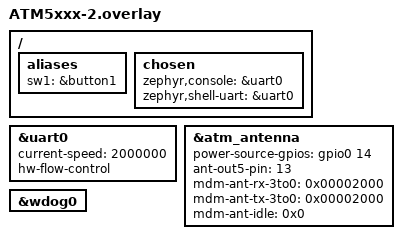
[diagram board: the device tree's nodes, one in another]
/*
 * Copyright (c) 2026 Atmosic
 *
 * SPDX-License-Identifier: LicenseRef-Atmosic
 */

/ {
	aliases {
		sw1 = &button1;
	};

	chosen {
		zephyr,console = &uart0;
		zephyr,shell-uart = &uart0;
	};
};

&uart0 {
	status = "okay";
	current-speed = <2000000>;
	hw-flow-control;
};

&atm_antenna {
	status = "okay";
	power-source-gpios = <&gpio0 14 GPIO_ACTIVE_HIGH>;
	ant-out5-pin = <13>;
	mdm-ant-rx-3to0 = <0x00002000>;
	mdm-ant-tx-3to0 = <0x00002000>;
	mdm-ant-idle = <0x0>;
};

&wdog0 {
	status = "okay";
};
